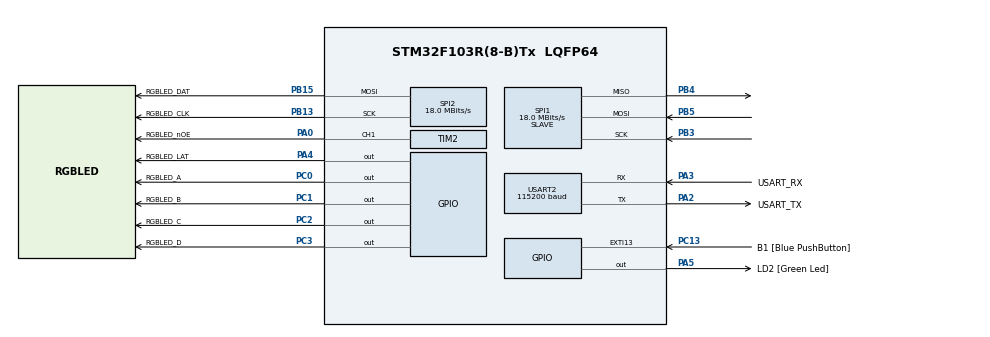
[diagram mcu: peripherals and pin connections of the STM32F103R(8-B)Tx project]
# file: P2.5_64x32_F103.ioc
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Dma.Request0=SPI1_RX
Dma.Request1=SPI2_TX
Dma.Request2=USART2_TX
Dma.SPI1_RX.0.Direction=DMA_PERIPH_TO_MEMORY
Dma.SPI1_RX.0.Instance=DMA1_Channel2
Dma.SPI1_RX.0.MemDataAlignment=DMA_MDATAALIGN_BYTE
Dma.SPI1_RX.0.MemInc=DMA_MINC_ENABLE
Dma.SPI1_RX.0.Mode=DMA_NORMAL
Dma.SPI1_RX.0.PeriphDataAlignment=DMA_PDATAALIGN_BYTE
Dma.SPI1_RX.0.PeriphInc=DMA_PINC_DISABLE
Dma.SPI1_RX.0.Priority=DMA_PRIORITY_MEDIUM
Dma.SPI2_TX.1.Direction=DMA_MEMORY_TO_PERIPH
Dma.SPI2_TX.1.Instance=DMA1_Channel5
Dma.SPI2_TX.1.MemDataAlignment=DMA_MDATAALIGN_BYTE
Dma.SPI2_TX.1.MemInc=DMA_MINC_ENABLE
Dma.SPI2_TX.1.Mode=DMA_NORMAL
Dma.SPI2_TX.1.PeriphDataAlignment=DMA_PDATAALIGN_BYTE
Dma.SPI2_TX.1.PeriphInc=DMA_PINC_DISABLE
Dma.SPI2_TX.1.Priority=DMA_PRIORITY_VERY_HIGH
Dma.USART2_TX.2.Direction=DMA_MEMORY_TO_PERIPH
Dma.USART2_TX.2.Instance=DMA1_Channel7
Dma.USART2_TX.2.MemDataAlignment=DMA_MDATAALIGN_BYTE
Dma.USART2_TX.2.MemInc=DMA_MINC_ENABLE
Dma.USART2_TX.2.Mode=DMA_NORMAL
Dma.USART2_TX.2.PeriphDataAlignment=DMA_PDATAALIGN_BYTE
Dma.USART2_TX.2.PeriphInc=DMA_PINC_DISABLE
Dma.USART2_TX.2.Priority=DMA_PRIORITY_LOW
Mcu.Family=STM32F1
Mcu.Name=STM32F103R(8-B)Tx
Mcu.Package=LQFP64
NVIC.DMA1_Channel2_IRQn=true\:1\:0\:true\:false\:true\:false\:true
NVIC.DMA1_Channel5_IRQn=true\:0\:0\:false\:false\:true\:false\:true
NVIC.DMA1_Channel7_IRQn=true\:0\:0\:false\:false\:true\:false\:true
NVIC.EXTI15_10_IRQn=true\:0\:0\:false\:false\:true\:true\:true
NVIC.PriorityGroup=NVIC_PRIORITYGROUP_4
NVIC.TIM2_IRQn=true\:2\:0\:true\:false\:true\:true\:true
NVIC.TIM3_IRQn=true\:5\:0\:true\:false\:true\:true\:true
NVIC.USART2_IRQn=true\:3\:0\:true\:false\:true\:true\:true
PA0-WKUP.GPIO_Label=RGBLED_nOE
PA0-WKUP.GPIO_Speed=GPIO_SPEED_FREQ_HIGH
PA0-WKUP.Signal=S_TIM2_CH1_ETR
PA13.Mode=Serial_Wire
PA13.Signal=SYS_JTMS-SWDIO
PA14.Mode=Serial_Wire
PA14.Signal=SYS_JTCK-SWCLK
PA2.GPIO_Label=USART_TX
PA2.GPIO_Mode=GPIO_MODE_AF_PP
PA2.GPIO_PuPd=GPIO_NOPULL
PA2.GPIO_Speed=GPIO_SPEED_FREQ_LOW
PA2.Mode=Asynchronous
PA2.Signal=USART2_TX
PA3.GPIO_Label=USART_RX
PA3.GPIO_Mode=GPIO_MODE_AF_PP
PA3.GPIO_PuPd=GPIO_NOPULL
PA3.GPIO_Speed=GPIO_SPEED_FREQ_LOW
PA3.Mode=Asynchronous
PA3.Signal=USART2_RX
PA4.GPIO_Label=RGBLED_LAT
PA4.GPIO_Speed=GPIO_SPEED_FREQ_HIGH
PA4.Signal=GPIO_Output
PA5.GPIO_Label=LD2 [Green Led]
PA5.GPIO_ModeDefaultOutputPP=GPIO_MODE_OUTPUT_PP
PA5.GPIO_PuPd=GPIO_NOPULL
PA5.GPIO_Speed=GPIO_SPEED_FREQ_LOW
PA5.Signal=GPIO_Output
PB13.GPIO_Label=RGBLED_CLK
PB13.Mode=TX_Only_Simplex_Unidirect_Master
PB13.Signal=SPI2_SCK
PB15.GPIO_Label=RGBLED_DAT
PB15.Mode=TX_Only_Simplex_Unidirect_Master
PB15.Signal=SPI2_MOSI
PB3.Mode=Full_Duplex_Slave
PB3.Signal=SPI1_SCK
PB4.Mode=Full_Duplex_Slave
PB4.Signal=SPI1_MISO
PB5.Mode=Full_Duplex_Slave
PB5.Signal=SPI1_MOSI
PC0.GPIO_Label=RGBLED_A
PC0.GPIO_Speed=GPIO_SPEED_FREQ_MEDIUM
PC0.Signal=GPIO_Output
PC1.GPIO_Label=RGBLED_B
PC1.GPIO_Speed=GPIO_SPEED_FREQ_MEDIUM
PC1.Signal=GPIO_Output
PC13-TAMPER-RTC.GPIO_Label=B1 [Blue PushButton]
PC13-TAMPER-RTC.GPIO_PuPd=GPIO_NOPULL
PC13-TAMPER-RTC.Signal=GPXTI13
PC14-OSC32_IN.Mode=LSE-External-Oscillator
PC14-OSC32_IN.Signal=RCC_OSC32_IN
PC15-OSC32_OUT.Mode=LSE-External-Oscillator
PC15-OSC32_OUT.Signal=RCC_OSC32_OUT
PC2.GPIO_Label=RGBLED_C
PC2.GPIO_Speed=GPIO_SPEED_FREQ_MEDIUM
PC2.Signal=GPIO_Output
PC3.GPIO_Label=RGBLED_D
PC3.GPIO_Speed=GPIO_SPEED_FREQ_MEDIUM
PC3.Signal=GPIO_Output
PD0-OSC_IN.Mode=HSE-External-Oscillator
PD0-OSC_IN.Signal=RCC_OSC_IN
PD1-OSC_OUT.Mode=HSE-External-Oscillator
PD1-OSC_OUT.Signal=RCC_OSC_OUT
ProjectManager.HeapSize=0x200
ProjectManager.StackSize=0x400
ProjectManager.TargetToolchain=STM32CubeIDE
RCC.AHBFreq_Value=72000000
RCC.APB1CLKDivider=RCC_HCLK_DIV2
RCC.APB1Freq_Value=36000000
RCC.APB1TimFreq_Value=72000000
RCC.APB2Freq_Value=72000000
RCC.APB2TimFreq_Value=72000000
RCC.HCLKFreq_Value=72000000
RCC.PLLMUL=RCC_PLL_MUL9
RCC.PLLSourceVirtual=RCC_PLLSOURCE_HSE
RCC.RTCClockSelection=RCC_RTCCLKSOURCE_LSE
RCC.SYSCLKFreq_VALUE=72000000
RCC.SYSCLKSource=RCC_SYSCLKSOURCE_PLLCLK
RCC.USBFreq_Value=72000000
SH.S_TIM2_CH1_ETR.0=TIM2_CH1,PWM Generation1 CH1
SPI1.BaudRatePrescaler=SPI_BAUDRATEPRESCALER_4
SPI1.CalculateBaudRate=18.0 MBits/s
SPI1.Direction=SPI_DIRECTION_2LINES
SPI1.Mode=SPI_MODE_SLAVE
SPI1.VirtualType=VM_SLAVE
SPI2.CalculateBaudRate=18.0 MBits/s
SPI2.Direction=SPI_DIRECTION_2LINES
SPI2.Mode=SPI_MODE_MASTER
SPI2.VirtualType=VM_MASTER
TIM2.AutoReloadPreload=TIM_AUTORELOAD_PRELOAD_ENABLE
TIM2.Channel-PWM\ Generation1\ CH1=TIM_CHANNEL_1
TIM2.OCMode_PWM-PWM\ Generation1\ CH1=TIM_OCMODE_PWM2
TIM2.OCPolarity_1=TIM_OCPOLARITY_LOW
TIM2.Period=29951
TIM3.AutoReloadPreload=TIM_AUTORELOAD_PRELOAD_ENABLE
TIM3.Period=37499
TIM3.Prescaler=31
USART2.BaudRate=115200
USART2.VirtualMode=VM_ASYNC
VP_TIM2_VS_ClockSourceINT.Mode=Internal
VP_TIM3_VS_ClockSourceINT.Mode=Internal
board=NUCLEO-F103RB

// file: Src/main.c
/* USER CODE BEGIN Header */
/**
  ******************************************************************************
  * @file           : main.c
  * @brief          : Main program body
  ******************************************************************************
  * @attention
  *
  * <h2><center>&copy; Copyright (c) 2021 STMicroelectronics.
  * All rights reserved.</center></h2>
  *
  * This software component is licensed by ST under BSD 3-Clause license,
  * the "License"; You may not use this file except in compliance with the
  * License. You may obtain a copy of the License at:
  *                        opensource.org/licenses/BSD-3-Clause
  *
  ******************************************************************************
  */
/* USER CODE END Header */

#include "main.h"
#include "dma.h"
#include "spi.h"
#include "tim.h"
#include "usart.h"
#include "gpio.h"

/* USER CODE BEGIN Includes */
#include "logger/logger_api.h"
#include "display/rgb_output.h"
/* USER CODE END Includes */

/* USER CODE BEGIN PD */
#define LD2_ON      GPIOA->BSRR=LD2_Pin
#define LD2_OFF     GPIOA->BRR=LD2_Pin
/* USER CODE END PD */

void SystemClock_Config(void);

int main(void)
{
  /* USER CODE BEGIN 1 */
    uint8_t i = 0;
  /* USER CODE END 1 */

  /* MCU Configuration--------------------------------------------------------*/

  /* Reset of all peripherals, Initializes the Flash interface and the Systick. */

  LL_APB2_GRP1_EnableClock(LL_APB2_GRP1_PERIPH_AFIO);
  LL_APB1_GRP1_EnableClock(LL_APB1_GRP1_PERIPH_PWR);

  NVIC_SetPriorityGrouping(NVIC_PRIORITYGROUP_4);

  /* System interrupt init*/

  /** NOJTAG: JTAG-DP Disabled and SW-DP Enabled
  */
  LL_GPIO_AF_Remap_SWJ_NOJTAG();

  /* Configure the system clock */
  SystemClock_Config();

  /* Initialize all configured peripherals */
  MX_GPIO_Init();
  MX_DMA_Init();
  MX_SPI1_Init();
  MX_SPI2_Init();
  MX_TIM2_Init();
  MX_TIM3_Init();
  MX_USART2_UART_Init();
  /* USER CODE BEGIN 2 */
  NW_UART_Send("Hello\r\n", 7);

  NW_LED_Init();
  /* USER CODE END 2 */

  /* Infinite loop */
  /* USER CODE BEGIN WHILE */
    while (1)
    {
        /** Check for priority table to fetch tasks */

    /* USER CODE END WHILE */

    }
}

void SystemClock_Config(void)
{
  LL_FLASH_SetLatency(LL_FLASH_LATENCY_2);

   if(LL_FLASH_GetLatency() != LL_FLASH_LATENCY_2)
  {
    Error_Handler();
  }
  LL_RCC_HSE_Enable();

   /* Wait till HSE is ready */
  while(LL_RCC_HSE_IsReady() != 1)
  {

  }
  LL_RCC_PLL_ConfigDomain_SYS(LL_RCC_PLLSOURCE_HSE_DIV_1, LL_RCC_PLL_MUL_9);
  LL_RCC_PLL_Enable();

   /* Wait till PLL is ready */
  while(LL_RCC_PLL_IsReady() != 1)
  {

  }
  LL_RCC_SetAHBPrescaler(LL_RCC_SYSCLK_DIV_1);
  LL_RCC_SetAPB1Prescaler(LL_RCC_APB1_DIV_2);
  LL_RCC_SetAPB2Prescaler(LL_RCC_APB2_DIV_1);
  LL_RCC_SetSysClkSource(LL_RCC_SYS_CLKSOURCE_PLL);

   /* Wait till System clock is ready */
  while(LL_RCC_GetSysClkSource() != LL_RCC_SYS_CLKSOURCE_STATUS_PLL)
  {

  }
  LL_Init1msTick(72000000);
  LL_SetSystemCoreClock(72000000);
}

void Error_Handler(void)
{
  /* USER CODE BEGIN Error_Handler_Debug */
  /* User can add his own implementation to report the HAL error return state */
  static int enterred = 0;
  if (enterred == 0)
  {
    NW_Logger_Report(LOGGER_FATAL, "Unhandled exception.");
    enterred = 1;
  }
  /* USER CODE END Error_Handler_Debug */
}

/************************ (C) COPYRIGHT STMicroelectronics *****END OF FILE****/
